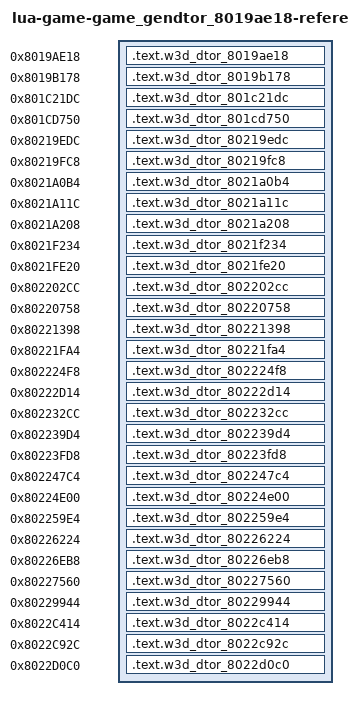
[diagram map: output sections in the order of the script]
/* Generated reference-only placements. All bodies are source-built. */
OUTPUT_FORMAT("elf32-powerpc")
OUTPUT_ARCH(powerpc)
ENTRY(w3d_dtor_8019ae18)
_SDA_BASE_ = 0x804b2540;
_SDA2_BASE_ = 0x804c2540;
fn_801ea138 = 0x801ea138;
fn_801ea740 = 0x801ea740;
fn_801fe1f8 = 0x801fe1f8;
fn_8020c5c4 = 0x8020c5c4;
fn_80210990 = 0x80210990;
fn_8021f234 = 0x8021f234;
fn_8021fe20 = 0x8021fe20;
fn_802224f8 = 0x802224f8;
fn_80341588 = 0x80341588;
w3d_vtable_80413580 = 0x80413580;
w3d_vtable_804135a8 = 0x804135a8;
w3d_vtable_80414d58 = 0x80414d58;
w3d_vtable_80415f38 = 0x80415f38;
w3d_vtable_804198c8 = 0x804198c8;
w3d_vtable_80419988 = 0x80419988;
w3d_vtable_80419a48 = 0x80419a48;
w3d_vtable_80419b08 = 0x80419b08;
w3d_vtable_80419bc8 = 0x80419bc8;
w3d_vtable_80419f88 = 0x80419f88;
w3d_vtable_80419fd8 = 0x80419fd8;
w3d_vtable_8041a000 = 0x8041a000;
w3d_vtable_8041a0f0 = 0x8041a0f0;
w3d_vtable_8041a168 = 0x8041a168;
w3d_vtable_8041a1b8 = 0x8041a1b8;
w3d_vtable_8041a280 = 0x8041a280;
w3d_vtable_8041a2d0 = 0x8041a2d0;
w3d_vtable_8041a370 = 0x8041a370;
w3d_vtable_8041a398 = 0x8041a398;
w3d_vtable_8041a3c0 = 0x8041a3c0;
w3d_vtable_8041a3e8 = 0x8041a3e8;
w3d_vtable_8041a410 = 0x8041a410;
w3d_vtable_8041a438 = 0x8041a438;
w3d_vtable_8041a488 = 0x8041a488;
w3d_vtable_8041a4b0 = 0x8041a4b0;
w3d_vtable_8041a500 = 0x8041a500;
w3d_vtable_8041a578 = 0x8041a578;
w3d_vtable_8041a5a0 = 0x8041a5a0;
w3d_vtable_8041a5c8 = 0x8041a5c8;
w3d_vtable_8041a5f0 = 0x8041a5f0;
SECTIONS {
  .text.w3d_dtor_8019ae18 0x8019ae18 : { *(.text.w3d_dtor_8019ae18) }
  .text.w3d_dtor_8019b178 0x8019b178 : { *(.text.w3d_dtor_8019b178) }
  .text.w3d_dtor_801c21dc 0x801c21dc : { *(.text.w3d_dtor_801c21dc) }
  .text.w3d_dtor_801cd750 0x801cd750 : { *(.text.w3d_dtor_801cd750) }
  .text.w3d_dtor_80219edc 0x80219edc : { *(.text.w3d_dtor_80219edc) }
  .text.w3d_dtor_80219fc8 0x80219fc8 : { *(.text.w3d_dtor_80219fc8) }
  .text.w3d_dtor_8021a0b4 0x8021a0b4 : { *(.text.w3d_dtor_8021a0b4) }
  .text.w3d_dtor_8021a11c 0x8021a11c : { *(.text.w3d_dtor_8021a11c) }
  .text.w3d_dtor_8021a208 0x8021a208 : { *(.text.w3d_dtor_8021a208) }
  .text.w3d_dtor_8021f234 0x8021f234 : { *(.text.w3d_dtor_8021f234) }
  .text.w3d_dtor_8021fe20 0x8021fe20 : { *(.text.w3d_dtor_8021fe20) }
  .text.w3d_dtor_802202cc 0x802202cc : { *(.text.w3d_dtor_802202cc) }
  .text.w3d_dtor_80220758 0x80220758 : { *(.text.w3d_dtor_80220758) }
  .text.w3d_dtor_80221398 0x80221398 : { *(.text.w3d_dtor_80221398) }
  .text.w3d_dtor_80221fa4 0x80221fa4 : { *(.text.w3d_dtor_80221fa4) }
  .text.w3d_dtor_802224f8 0x802224f8 : { *(.text.w3d_dtor_802224f8) }
  .text.w3d_dtor_80222d14 0x80222d14 : { *(.text.w3d_dtor_80222d14) }
  .text.w3d_dtor_802232cc 0x802232cc : { *(.text.w3d_dtor_802232cc) }
  .text.w3d_dtor_802239d4 0x802239d4 : { *(.text.w3d_dtor_802239d4) }
  .text.w3d_dtor_80223fd8 0x80223fd8 : { *(.text.w3d_dtor_80223fd8) }
  .text.w3d_dtor_802247c4 0x802247c4 : { *(.text.w3d_dtor_802247c4) }
  .text.w3d_dtor_80224e00 0x80224e00 : { *(.text.w3d_dtor_80224e00) }
  .text.w3d_dtor_802259e4 0x802259e4 : { *(.text.w3d_dtor_802259e4) }
  .text.w3d_dtor_80226224 0x80226224 : { *(.text.w3d_dtor_80226224) }
  .text.w3d_dtor_80226eb8 0x80226eb8 : { *(.text.w3d_dtor_80226eb8) }
  .text.w3d_dtor_80227560 0x80227560 : { *(.text.w3d_dtor_80227560) }
  .text.w3d_dtor_80229944 0x80229944 : { *(.text.w3d_dtor_80229944) }
  .text.w3d_dtor_8022c414 0x8022c414 : { *(.text.w3d_dtor_8022c414) }
  .text.w3d_dtor_8022c92c 0x8022c92c : { *(.text.w3d_dtor_8022c92c) }
  .text.w3d_dtor_8022d0c0 0x8022d0c0 : { *(.text.w3d_dtor_8022d0c0) }
  /DISCARD/ : { *(.text*) *(.rodata*) *(.data*) *(.bss*) *(.sdata*) *(.sbss*) *(.comment) }
}
